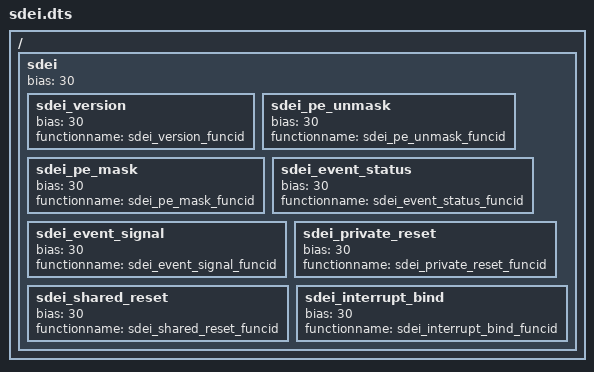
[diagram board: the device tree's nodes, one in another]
/*
 * Copyright (c) 2024, Arm Limited. All rights reserved.
 *
 * SPDX-License-Identifier: BSD-3-Clause
 */

/dts-v1/;

/ {

	sdei {
		bias = <30>;
		sdei_version {
			bias = <30>;
			functionname = "sdei_version_funcid";
		};
		sdei_pe_unmask {
			bias = <30>;
			functionname = "sdei_pe_unmask_funcid";
		};
		sdei_pe_mask {
			bias = <30>;
			functionname = "sdei_pe_mask_funcid";
		};
		sdei_event_status {
			bias = <30>;
			functionname = "sdei_event_status_funcid";
		};
		sdei_event_signal {
			bias = <30>;
			functionname = "sdei_event_signal_funcid";
		};
		sdei_private_reset {
			bias = <30>;
			functionname = "sdei_private_reset_funcid";
		};
		sdei_shared_reset {
			bias = <30>;
			functionname = "sdei_shared_reset_funcid";
		};
		sdei_interrupt_bind {
			bias = <30>;
			functionname = "sdei_interrupt_bind_funcid";
		};
	};

};
